# PIC16LF1619 register map
Vendor: Microchip
Architecture 16Exxx. Special function registers and configuration words.
Registers are 8-bit, read-write, reset 0x0 unless marked. A register's access mark holds for its fields unless they carry their own. Addresses are absolute, and some are shared; only a register's first bit layout is shown; lines under a group give offsets from that group; [hi:lo] are bit positions; {n}, {i} and the like mark numbered series; 'fields as' and 'values as' point back to an identical list; <NAME> marks a mode.

## Further device data
pins=1: VDD; 2: RA5/CLKIN; 3: RA4/AN3/CLKOUT; 4: RA3/VPP/nMCLR/MCLR; 5: RC5/HIDC5; 6: RC4/HIDC4; 7: RC3/AN7/C1IN3-/C2IN3-; 8: RC6/AN8; 9: RC7/AN9; 10: RB7; 11: RB6; 12: RB5/AN11; 13: RB4/I2C/AN10; 14: RC2/AN6/C1IN2-/C2IN2-; 15: RC1/AN5/C1IN1-/C2IN1-; 16: RC0/AN4/C2IN+; 17: RA2/AN2/ZCDIN; 18: RA1/AN1/C2IN0-/C1IN0-/VREF+/ICSPCLK; 19: RA0/AN0/C1IN+/DACOUT/ICSPDAT; 20: VSS

## tmr
0x1A T2TMR — 8-bit period timer
  [7:0] TMR
0x1B T2PR reset 0xFF
  [7:0] PR
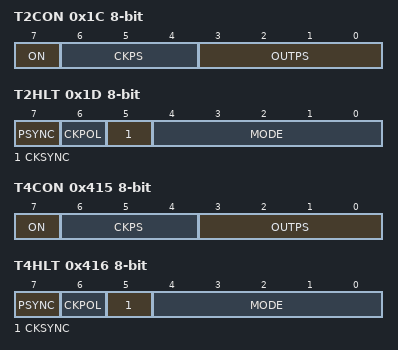
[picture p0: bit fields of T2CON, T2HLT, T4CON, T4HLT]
0x1C T2CON
  [7] ON, [6:4] CKPS, [3:0] OUTPS
0x1D T2HLT
  [7] PSYNC, [6] CKPOL, [5] CKSYNC, [4:0] MODE
0x1E T2CLKCON
  [3:0] CS
0x1F T2RST
  [3:0] RSEL
0x413 T4TMR — 8-bit period timer
  [7:0] TMR
0x414 T4PR reset 0xFF
  [7:0] PR
0x415 T4CON
  [7] ON, [6:4] CKPS, [3:0] OUTPS
0x416 T4HLT
  [7] PSYNC, [6] CKPOL, [5] CKSYNC, [4:0] MODE
0x417 T4CLKCON
  [3:0] CS
0x418 T4RST
  [3:0] RSEL
0x41A T6TMR — 8-bit period timer
  [7:0] TMR
0x41B T6PR reset 0xFF
  [7:0] PR
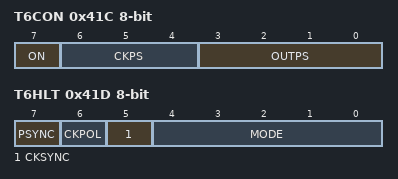
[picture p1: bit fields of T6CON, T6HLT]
0x41C T6CON
  [7] ON, [6:4] CKPS, [3:0] OUTPS
0x41D T6HLT
  [7] PSYNC, [6] CKPOL, [5] CKSYNC, [4:0] MODE
0x41E T6CLKCON
  [3:0] CS
0x41F T6RST
  [3:0] RSEL

## mssp
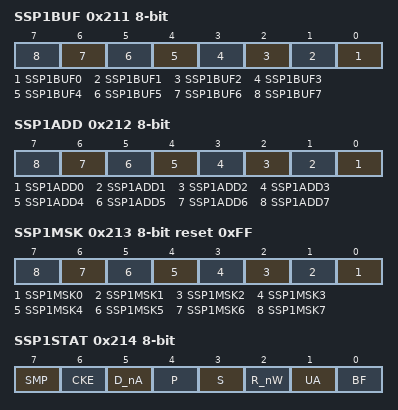
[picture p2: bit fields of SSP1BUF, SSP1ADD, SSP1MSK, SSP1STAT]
0x211 SSP1BUF reset not defined — (power-on value xxxxxxxx)
  [n] SSP1BUF{n} (n=0..7)
0x212 SSP1ADD
  [n] SSP1ADD{n} (n=0..7)
0x213 SSP1MSK reset 0xFF
  [n] SSP1MSK{n} (n=0..7)
0x214 SSP1STAT
  [7] SMP, [6] CKE, [5] D_nA ro, [4] P ro, [3] S ro, [2] R_nW ro, [1] UA ro, [0] BF ro
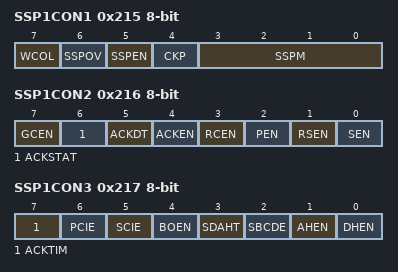
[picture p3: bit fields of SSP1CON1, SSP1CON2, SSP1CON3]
0x215 SSP1CON1
  [7] WCOL ro, [6] SSPOV ro, [5] SSPEN, [4] CKP, [3:0] SSPM
0x216 SSP1CON2
  [7] GCEN, [6] ACKSTAT ro, [5] ACKDT, [4] ACKEN, [3] RCEN, [2] PEN, [1] RSEN, [0] SEN
0x217 SSP1CON3
  [7] ACKTIM ro, [6] PCIE, [5] SCIE, [4] BOEN, [3] SDAHT, [2] SBCDE, [1] AHEN, [0] DHEN

## ccp
0x291 CCPR1L reset not defined — (power-on value xxxxxxxx)
  [7:0] RL
0x292 CCPR1H reset not defined — (power-on value xxxxxxxx)
  [7:0] RH
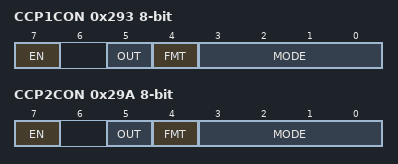
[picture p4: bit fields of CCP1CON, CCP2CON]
0x293 CCP1CON
  [7] EN, [5] OUT ro, [4] FMT, [3:0] MODE
0x294 CCP1CAP
  [2:0] CTS
0x298 CCPR2L reset not defined — (power-on value xxxxxxxx)
  [7:0] RL
0x299 CCPR2H reset not defined — (power-on value xxxxxxxx)
  [7:0] RH
0x29A CCP2CON
  [7] EN, [5] OUT ro, [4] FMT, [3:0] MODE
0x29B CCP2CAP
  [2:0] CTS

## math_progmac
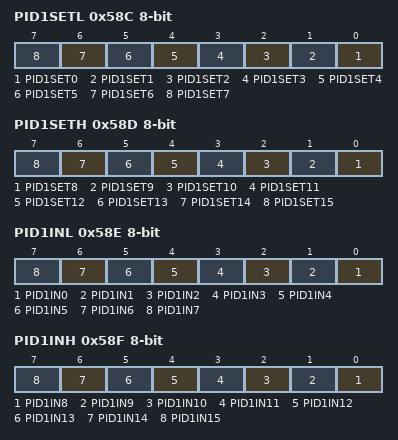
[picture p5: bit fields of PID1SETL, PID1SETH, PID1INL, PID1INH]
0x58C PID1SETL
  [n] PID1SET{n} (n=0..7)
0x58D PID1SETH
  [n-8] PID1SET{n} (n=8..15)
0x58E PID1INL reset not defined — (power-on value xxxxxxxx)
  [n] PID1IN{n} (n=0..7)
0x58F PID1INH reset not defined — (power-on value xxxxxxxx)
  [n-8] PID1IN{n} (n=8..15)
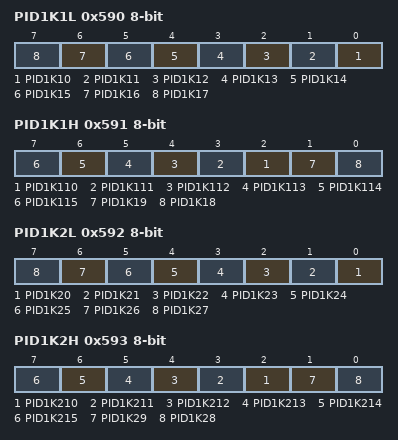
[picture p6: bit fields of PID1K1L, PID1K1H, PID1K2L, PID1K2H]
0x590 PID1K1L reset not defined — (power-on value xxxxxxxx)
  [n-10] PID1K{n} (n=10..17)
0x591 PID1K1H reset not defined — (power-on value xxxxxxxx)
  [n-108] PID1K{n} (n=110..115), [1] PID1K19, [0] PID1K18
0x592 PID1K2L reset not defined — (power-on value xxxxxxxx)
  [n-20] PID1K{n} (n=20..27)
0x593 PID1K2H reset not defined — (power-on value xxxxxxxx)
  [n-208] PID1K{n} (n=210..215), [1] PID1K29, [0] PID1K28
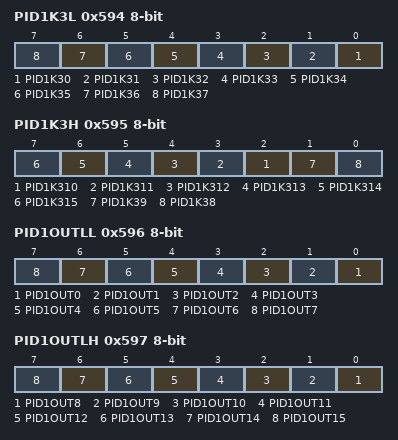
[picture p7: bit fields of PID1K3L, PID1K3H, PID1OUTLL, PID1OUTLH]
0x594 PID1K3L reset not defined — (power-on value xxxxxxxx)
  [n-30] PID1K{n} (n=30..37)
0x595 PID1K3H reset not defined — (power-on value xxxxxxxx)
  [n-308] PID1K{n} (n=310..315), [1] PID1K39, [0] PID1K38
0x596 PID1OUTLL
  [n] PID1OUT{n} (n=0..7)
0x597 PID1OUTLH
  [n-8] PID1OUT{n} (n=8..15)
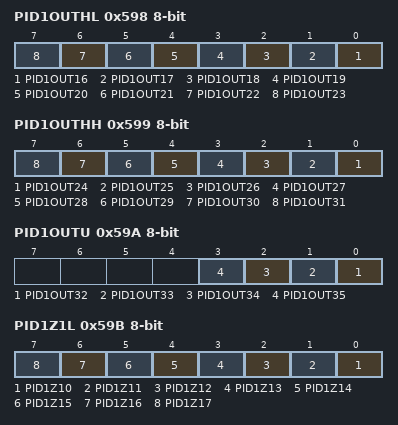
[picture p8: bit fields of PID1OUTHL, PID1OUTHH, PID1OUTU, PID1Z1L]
0x598 PID1OUTHL
  [n-16] PID1OUT{n} (n=16..23)
0x599 PID1OUTHH
  [n-24] PID1OUT{n} (n=24..31)
0x59A PID1OUTU
  [n-32] PID1OUT{n} (n=32..35)
0x59B PID1Z1L
  [n-10] PID1Z{n} (n=10..17)
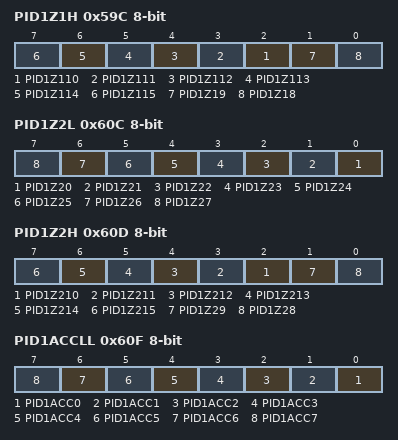
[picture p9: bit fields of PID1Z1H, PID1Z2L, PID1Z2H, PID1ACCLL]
0x59C PID1Z1H
  [n-108] PID1Z{n} (n=110..115), [1] PID1Z19, [0] PID1Z18
0x59D PID1Z1U
  [0] PID1Z116
0x60C PID1Z2L
  [n-20] PID1Z{n} (n=20..27)
0x60D PID1Z2H
  [n-208] PID1Z{n} (n=210..215), [1] PID1Z29, [0] PID1Z28
0x60E PID1Z2U
  [0] PID1Z216
0x60F PID1ACCLL
  [n] PID1ACC{n} (n=0..7)
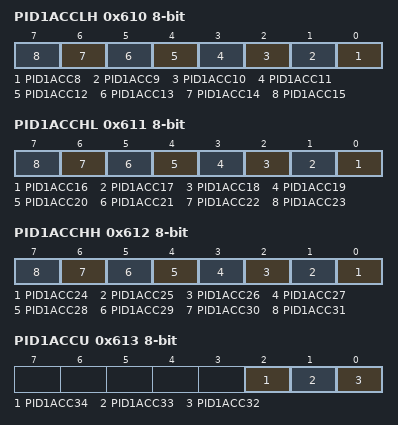
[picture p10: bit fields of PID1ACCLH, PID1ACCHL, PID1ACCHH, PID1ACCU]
0x610 PID1ACCLH
  [n-8] PID1ACC{n} (n=8..15)
0x611 PID1ACCHL
  [n-16] PID1ACC{n} (n=16..23)
0x612 PID1ACCHH
  [n-24] PID1ACC{n} (n=24..31)
0x613 PID1ACCU
  [2] PID1ACC34, [1] PID1ACC33, [0] PID1ACC32
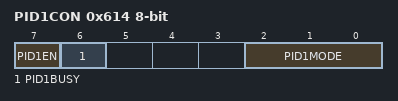
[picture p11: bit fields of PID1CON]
0x614 PID1CON
  [7] PID1EN, [6] PID1BUSY ro, [2:0] PID1MODE
